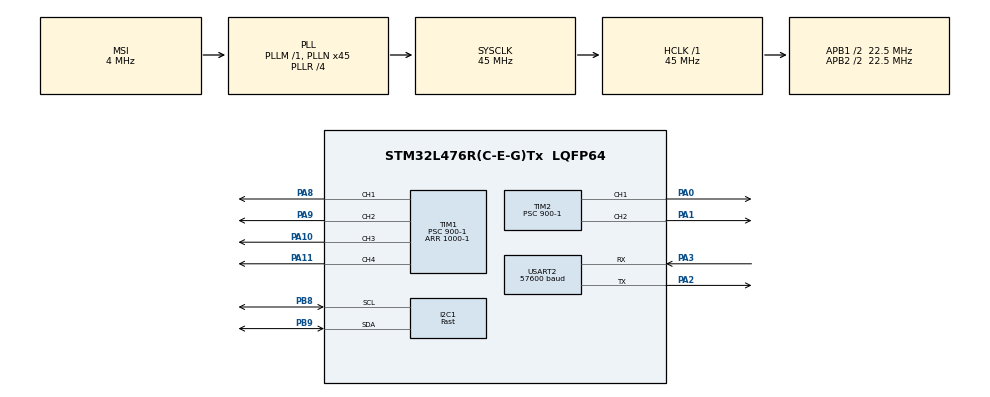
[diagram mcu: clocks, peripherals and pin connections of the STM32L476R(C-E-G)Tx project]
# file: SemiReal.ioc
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Dma.Request0=USART2_RX
Dma.Request1=USART2_TX
Dma.USART2_RX.0.Direction=DMA_PERIPH_TO_MEMORY
Dma.USART2_RX.0.Instance=DMA1_Channel6
Dma.USART2_RX.0.MemDataAlignment=DMA_MDATAALIGN_BYTE
Dma.USART2_RX.0.MemInc=DMA_MINC_ENABLE
Dma.USART2_RX.0.Mode=DMA_CIRCULAR
Dma.USART2_RX.0.PeriphDataAlignment=DMA_PDATAALIGN_BYTE
Dma.USART2_RX.0.PeriphInc=DMA_PINC_DISABLE
Dma.USART2_RX.0.Priority=DMA_PRIORITY_LOW
Dma.USART2_TX.1.Direction=DMA_MEMORY_TO_PERIPH
Dma.USART2_TX.1.Instance=DMA1_Channel7
Dma.USART2_TX.1.MemDataAlignment=DMA_MDATAALIGN_BYTE
Dma.USART2_TX.1.MemInc=DMA_MINC_ENABLE
Dma.USART2_TX.1.Mode=DMA_NORMAL
Dma.USART2_TX.1.PeriphDataAlignment=DMA_PDATAALIGN_BYTE
Dma.USART2_TX.1.PeriphInc=DMA_PINC_DISABLE
Dma.USART2_TX.1.Priority=DMA_PRIORITY_LOW
I2C1.I2C_Speed_Mode=I2C_Fast
I2C1.Timing=0x00200A26
Mcu.Family=STM32L4
Mcu.Name=STM32L476R(C-E-G)Tx
Mcu.Package=LQFP64
NVIC.DMA1_Channel6_IRQn=true\:0\:0\:false\:false\:true\:false\:true\:true
NVIC.DMA1_Channel7_IRQn=true\:0\:0\:false\:false\:true\:false\:true\:true
NVIC.PriorityGroup=NVIC_PRIORITYGROUP_4
NVIC.USART2_IRQn=true\:0\:0\:false\:false\:true\:true\:true\:true
PA0.Signal=S_TIM2_CH1
PA1.Signal=S_TIM2_CH2
PA10.Signal=S_TIM1_CH3
PA11.Signal=S_TIM1_CH4
PA2.Mode=Asynchronous
PA2.Signal=USART2_TX
PA3.Mode=Asynchronous
PA3.Signal=USART2_RX
PA8.Signal=S_TIM1_CH1
PA9.Signal=S_TIM1_CH2
PB8.Mode=I2C
PB8.Signal=I2C1_SCL
PB9.Mode=I2C
PB9.Signal=I2C1_SDA
PH0-OSC_IN\ (PH0).Mode=HSE-External-Oscillator
PH0-OSC_IN\ (PH0).Signal=RCC_OSC_IN
PH1-OSC_OUT\ (PH1).Mode=HSE-External-Oscillator
PH1-OSC_OUT\ (PH1).Signal=RCC_OSC_OUT
ProjectManager.HeapSize=0x200
ProjectManager.StackSize=0x400
ProjectManager.TargetToolchain=STM32CubeIDE
RCC.AHBFreq_Value=45000000
RCC.APB1CLKDivider=RCC_HCLK_DIV2
RCC.APB1Freq_Value=22500000
RCC.APB1TimFreq_Value=45000000
RCC.APB2CLKDivider=RCC_HCLK_DIV2
RCC.APB2Freq_Value=22500000
RCC.APB2TimFreq_Value=45000000
RCC.CortexFreq_Value=45000000
RCC.HCLKFreq_Value=45000000
RCC.HSE_VALUE=8000000
RCC.HSI_VALUE=16000000
RCC.LSE_VALUE=32768
RCC.MSI_VALUE=4000000
RCC.PLLN=45
RCC.PLLR=RCC_PLLR_DIV4
RCC.SYSCLKFreq_VALUE=45000000
RCC.SYSCLKSource=RCC_SYSCLKSOURCE_PLLCLK
RCC.VCOOutputFreq_Value=180000000
SH.S_TIM1_CH1.0=TIM1_CH1,PWM Generation1 CH1
SH.S_TIM1_CH2.0=TIM1_CH2,PWM Generation2 CH2
SH.S_TIM1_CH3.0=TIM1_CH3,PWM Generation3 CH3
SH.S_TIM1_CH4.0=TIM1_CH4,PWM Generation4 CH4
SH.S_TIM2_CH1.0=TIM2_CH1,PWM Generation1 CH1
SH.S_TIM2_CH2.0=TIM2_CH2,PWM Generation2 CH2
TIM1.AutoReloadPreload=TIM_AUTORELOAD_PRELOAD_ENABLE
TIM1.Channel-PWM\ Generation1\ CH1=TIM_CHANNEL_1
TIM1.Channel-PWM\ Generation2\ CH2=TIM_CHANNEL_2
TIM1.Channel-PWM\ Generation3\ CH3=TIM_CHANNEL_3
TIM1.Channel-PWM\ Generation4\ CH4=TIM_CHANNEL_4
TIM1.Period=1000-1
TIM1.Prescaler=900-1
TIM2.Channel-PWM\ Generation1\ CH1=TIM_CHANNEL_1
TIM2.Channel-PWM\ Generation2\ CH2=TIM_CHANNEL_2
TIM2.Period=1000-1
TIM2.Prescaler=900-1
USART2.BaudRate=57600
USART2.VirtualMode-Asynchronous=VM_ASYNC
VP_TIM1_VS_ClockSourceINT.Mode=Internal
VP_TIM2_VS_ClockSourceINT.Mode=Internal
board=custom

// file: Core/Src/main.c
/* USER CODE BEGIN Header */
/**
  ******************************************************************************
  * @file           : main.c
  * @brief          : Main program body
  ******************************************************************************
  * @attention
  *
  * Copyright (c) 2022 STMicroelectronics.
  * All rights reserved.
  *
  * This software is licensed under terms that can be found in the LICENSE file
  * in the root directory of this software component.
  * If no LICENSE file comes with this software, it is provided AS-IS.
  *
  ******************************************************************************
  */
/* USER CODE END Header */
#include "main.h"

/* USER CODE BEGIN Includes */

#include "mainpp.h"
#include "stdio.h"
#include <stdlib.h>
#include "math.h"
#include "stdint.h"
#include <string.h>
/* USER CODE END Includes */

 I2C_HandleTypeDef hi2c1;

TIM_HandleTypeDef htim1;
TIM_HandleTypeDef htim2;

UART_HandleTypeDef huart2;
DMA_HandleTypeDef hdma_usart2_rx;
DMA_HandleTypeDef hdma_usart2_tx;

void SystemClock_Config(void);
static void MX_GPIO_Init(void);
static void MX_DMA_Init(void);
static void MX_USART2_UART_Init(void);
static void MX_TIM2_Init(void);
static void MX_TIM1_Init(void);
static void MX_I2C1_Init(void);

int main(void)
{

  /* MCU Configuration--------------------------------------------------------*/

  /* Reset of all peripherals, Initializes the Flash interface and the Systick. */
  HAL_Init();

  /* Configure the system clock */
  SystemClock_Config();

  /* Initialize all configured peripherals */
  MX_GPIO_Init();
  MX_DMA_Init();
  MX_USART2_UART_Init();
  MX_TIM2_Init();
  MX_TIM1_Init();
  MX_I2C1_Init();
  /* USER CODE BEGIN 2 */
	HAL_TIM_PWM_Start(&htim1, TIM_CHANNEL_1);
	HAL_TIM_PWM_Start(&htim1, TIM_CHANNEL_2);
	HAL_TIM_PWM_Start(&htim1, TIM_CHANNEL_3);
	HAL_TIM_PWM_Start(&htim1, TIM_CHANNEL_4);
	HAL_TIM_PWM_Start(&htim2, TIM_CHANNEL_1);
	HAL_TIM_PWM_Start(&htim2, TIM_CHANNEL_2);

  /* USER CODE END 2 */

  /* Infinite loop */
  /* USER CODE BEGIN WHILE */

  setup(htim1, htim2);

  while (1)
  {
    /* USER CODE END WHILE */

    /* USER CODE BEGIN 3 */
	loop();
  }
  /* USER CODE END 3 */
}

void SystemClock_Config(void)
{
  RCC_OscInitTypeDef RCC_OscInitStruct = {0};
  RCC_ClkInitTypeDef RCC_ClkInitStruct = {0};

  /** Configure the main internal regulator output voltage
  */
  if (HAL_PWREx_ControlVoltageScaling(PWR_REGULATOR_VOLTAGE_SCALE1) != HAL_OK)
  {
    Error_Handler();
  }

  /** Initializes the RCC Oscillators according to the specified parameters
  * in the RCC_OscInitTypeDef structure.
  */
  RCC_OscInitStruct.OscillatorType = RCC_OSCILLATORTYPE_MSI;
  RCC_OscInitStruct.MSIState = RCC_MSI_ON;
  RCC_OscInitStruct.MSICalibrationValue = 0;
  RCC_OscInitStruct.MSIClockRange = RCC_MSIRANGE_6;
  RCC_OscInitStruct.PLL.PLLState = RCC_PLL_ON;
  RCC_OscInitStruct.PLL.PLLSource = RCC_PLLSOURCE_MSI;
  RCC_OscInitStruct.PLL.PLLM = 1;
  RCC_OscInitStruct.PLL.PLLN = 45;
  RCC_OscInitStruct.PLL.PLLP = RCC_PLLP_DIV7;
  RCC_OscInitStruct.PLL.PLLQ = RCC_PLLQ_DIV2;
  RCC_OscInitStruct.PLL.PLLR = RCC_PLLR_DIV4;
  if (HAL_RCC_OscConfig(&RCC_OscInitStruct) != HAL_OK)
  {
    Error_Handler();
  }

  /** Initializes the CPU, AHB and APB buses clocks
  */
  RCC_ClkInitStruct.ClockType = RCC_CLOCKTYPE_HCLK|RCC_CLOCKTYPE_SYSCLK
                              |RCC_CLOCKTYPE_PCLK1|RCC_CLOCKTYPE_PCLK2;
  RCC_ClkInitStruct.SYSCLKSource = RCC_SYSCLKSOURCE_PLLCLK;
  RCC_ClkInitStruct.AHBCLKDivider = RCC_SYSCLK_DIV1;
  RCC_ClkInitStruct.APB1CLKDivider = RCC_HCLK_DIV2;
  RCC_ClkInitStruct.APB2CLKDivider = RCC_HCLK_DIV2;

  if (HAL_RCC_ClockConfig(&RCC_ClkInitStruct, FLASH_LATENCY_2) != HAL_OK)
  {
    Error_Handler();
  }
}

static void MX_I2C1_Init(void)
{

  hi2c1.Instance = I2C1;
  hi2c1.Init.Timing = 0x00200A26;
  hi2c1.Init.OwnAddress1 = 0;
  hi2c1.Init.AddressingMode = I2C_ADDRESSINGMODE_7BIT;
  hi2c1.Init.DualAddressMode = I2C_DUALADDRESS_DISABLE;
  hi2c1.Init.OwnAddress2 = 0;
  hi2c1.Init.OwnAddress2Masks = I2C_OA2_NOMASK;
  hi2c1.Init.GeneralCallMode = I2C_GENERALCALL_DISABLE;
  hi2c1.Init.NoStretchMode = I2C_NOSTRETCH_DISABLE;
  if (HAL_I2C_Init(&hi2c1) != HAL_OK)
  {
    Error_Handler();
  }

  /** Configure Analogue filter
  */
  if (HAL_I2CEx_ConfigAnalogFilter(&hi2c1, I2C_ANALOGFILTER_ENABLE) != HAL_OK)
  {
    Error_Handler();
  }

  /** Configure Digital filter
  */
  if (HAL_I2CEx_ConfigDigitalFilter(&hi2c1, 0) != HAL_OK)
  {
    Error_Handler();
  }

}

static void MX_TIM1_Init(void)
{

  TIM_ClockConfigTypeDef sClockSourceConfig = {0};
  TIM_MasterConfigTypeDef sMasterConfig = {0};
  TIM_OC_InitTypeDef sConfigOC = {0};
  TIM_BreakDeadTimeConfigTypeDef sBreakDeadTimeConfig = {0};

  htim1.Instance = TIM1;
  htim1.Init.Prescaler = 900-1;
  htim1.Init.CounterMode = TIM_COUNTERMODE_UP;
  htim1.Init.Period = 1000-1;
  htim1.Init.ClockDivision = TIM_CLOCKDIVISION_DIV1;
  htim1.Init.RepetitionCounter = 0;
  htim1.Init.AutoReloadPreload = TIM_AUTORELOAD_PRELOAD_ENABLE;
  if (HAL_TIM_Base_Init(&htim1) != HAL_OK)
  {
    Error_Handler();
  }
  sClockSourceConfig.ClockSource = TIM_CLOCKSOURCE_INTERNAL;
  if (HAL_TIM_ConfigClockSource(&htim1, &sClockSourceConfig) != HAL_OK)
  {
    Error_Handler();
  }
  if (HAL_TIM_PWM_Init(&htim1) != HAL_OK)
  {
    Error_Handler();
  }
  sMasterConfig.MasterOutputTrigger = TIM_TRGO_RESET;
  sMasterConfig.MasterOutputTrigger2 = TIM_TRGO2_RESET;
  sMasterConfig.MasterSlaveMode = TIM_MASTERSLAVEMODE_DISABLE;
  if (HAL_TIMEx_MasterConfigSynchronization(&htim1, &sMasterConfig) != HAL_OK)
  {
    Error_Handler();
  }
  sConfigOC.OCMode = TIM_OCMODE_PWM1;
  sConfigOC.Pulse = 0;
  sConfigOC.OCPolarity = TIM_OCPOLARITY_HIGH;
  sConfigOC.OCNPolarity = TIM_OCNPOLARITY_HIGH;
  sConfigOC.OCFastMode = TIM_OCFAST_DISABLE;
  sConfigOC.OCIdleState = TIM_OCIDLESTATE_RESET;
  sConfigOC.OCNIdleState = TIM_OCNIDLESTATE_RESET;
  if (HAL_TIM_PWM_ConfigChannel(&htim1, &sConfigOC, TIM_CHANNEL_1) != HAL_OK)
  {
    Error_Handler();
  }
  if (HAL_TIM_PWM_ConfigChannel(&htim1, &sConfigOC, TIM_CHANNEL_2) != HAL_OK)
  {
    Error_Handler();
  }
  if (HAL_TIM_PWM_ConfigChannel(&htim1, &sConfigOC, TIM_CHANNEL_3) != HAL_OK)
  {
    Error_Handler();
  }
  if (HAL_TIM_PWM_ConfigChannel(&htim1, &sConfigOC, TIM_CHANNEL_4) != HAL_OK)
  {
    Error_Handler();
  }
  sBreakDeadTimeConfig.OffStateRunMode = TIM_OSSR_DISABLE;
  sBreakDeadTimeConfig.OffStateIDLEMode = TIM_OSSI_DISABLE;
  sBreakDeadTimeConfig.LockLevel = TIM_LOCKLEVEL_OFF;
  sBreakDeadTimeConfig.DeadTime = 0;
  sBreakDeadTimeConfig.BreakState = TIM_BREAK_DISABLE;
  sBreakDeadTimeConfig.BreakPolarity = TIM_BREAKPOLARITY_HIGH;
  sBreakDeadTimeConfig.BreakFilter = 0;
  sBreakDeadTimeConfig.Break2State = TIM_BREAK2_DISABLE;
  sBreakDeadTimeConfig.Break2Polarity = TIM_BREAK2POLARITY_HIGH;
  sBreakDeadTimeConfig.Break2Filter = 0;
  sBreakDeadTimeConfig.AutomaticOutput = TIM_AUTOMATICOUTPUT_DISABLE;
  if (HAL_TIMEx_ConfigBreakDeadTime(&htim1, &sBreakDeadTimeConfig) != HAL_OK)
  {
    Error_Handler();
  }
  HAL_TIM_MspPostInit(&htim1);

}

static void MX_TIM2_Init(void)
{

  TIM_ClockConfigTypeDef sClockSourceConfig = {0};
  TIM_MasterConfigTypeDef sMasterConfig = {0};
  TIM_OC_InitTypeDef sConfigOC = {0};

  htim2.Instance = TIM2;
  htim2.Init.Prescaler = 900-1;
  htim2.Init.CounterMode = TIM_COUNTERMODE_UP;
  htim2.Init.Period = 1000-1;
  htim2.Init.ClockDivision = TIM_CLOCKDIVISION_DIV1;
  htim2.Init.AutoReloadPreload = TIM_AUTORELOAD_PRELOAD_DISABLE;
  if (HAL_TIM_Base_Init(&htim2) != HAL_OK)
  {
    Error_Handler();
  }
  sClockSourceConfig.ClockSource = TIM_CLOCKSOURCE_INTERNAL;
  if (HAL_TIM_ConfigClockSource(&htim2, &sClockSourceConfig) != HAL_OK)
  {
    Error_Handler();
  }
  if (HAL_TIM_PWM_Init(&htim2) != HAL_OK)
  {
    Error_Handler();
  }
  sMasterConfig.MasterOutputTrigger = TIM_TRGO_RESET;
  sMasterConfig.MasterSlaveMode = TIM_MASTERSLAVEMODE_DISABLE;
  if (HAL_TIMEx_MasterConfigSynchronization(&htim2, &sMasterConfig) != HAL_OK)
  {
    Error_Handler();
  }
  sConfigOC.OCMode = TIM_OCMODE_PWM1;
  sConfigOC.Pulse = 0;
  sConfigOC.OCPolarity = TIM_OCPOLARITY_HIGH;
  sConfigOC.OCFastMode = TIM_OCFAST_DISABLE;
  if (HAL_TIM_PWM_ConfigChannel(&htim2, &sConfigOC, TIM_CHANNEL_1) != HAL_OK)
  {
    Error_Handler();
  }
  if (HAL_TIM_PWM_ConfigChannel(&htim2, &sConfigOC, TIM_CHANNEL_2) != HAL_OK)
  {
    Error_Handler();
  }
  HAL_TIM_MspPostInit(&htim2);

}

static void MX_USART2_UART_Init(void)
{

  huart2.Instance = USART2;
  huart2.Init.BaudRate = 57600;
  huart2.Init.WordLength = UART_WORDLENGTH_8B;
  huart2.Init.StopBits = UART_STOPBITS_1;
  huart2.Init.Parity = UART_PARITY_NONE;
  huart2.Init.Mode = UART_MODE_TX_RX;
  huart2.Init.HwFlowCtl = UART_HWCONTROL_NONE;
  huart2.Init.OverSampling = UART_OVERSAMPLING_16;
  huart2.Init.OneBitSampling = UART_ONE_BIT_SAMPLE_DISABLE;
  huart2.AdvancedInit.AdvFeatureInit = UART_ADVFEATURE_NO_INIT;
  if (HAL_UART_Init(&huart2) != HAL_OK)
  {
    Error_Handler();
  }

}

static void MX_DMA_Init(void)
{

  /* DMA controller clock enable */
  __HAL_RCC_DMA1_CLK_ENABLE();

  /* DMA interrupt init */
  /* DMA1_Channel6_IRQn interrupt configuration */
  HAL_NVIC_SetPriority(DMA1_Channel6_IRQn, 0, 0);
  HAL_NVIC_EnableIRQ(DMA1_Channel6_IRQn);
  /* DMA1_Channel7_IRQn interrupt configuration */
  HAL_NVIC_SetPriority(DMA1_Channel7_IRQn, 0, 0);
  HAL_NVIC_EnableIRQ(DMA1_Channel7_IRQn);

}

static void MX_GPIO_Init(void)
{

  /* GPIO Ports Clock Enable */
  __HAL_RCC_GPIOH_CLK_ENABLE();
  __HAL_RCC_GPIOA_CLK_ENABLE();
  __HAL_RCC_GPIOB_CLK_ENABLE();

}

void Error_Handler(void)
{
  __disable_irq();
  while (1)
  {
  }
}
